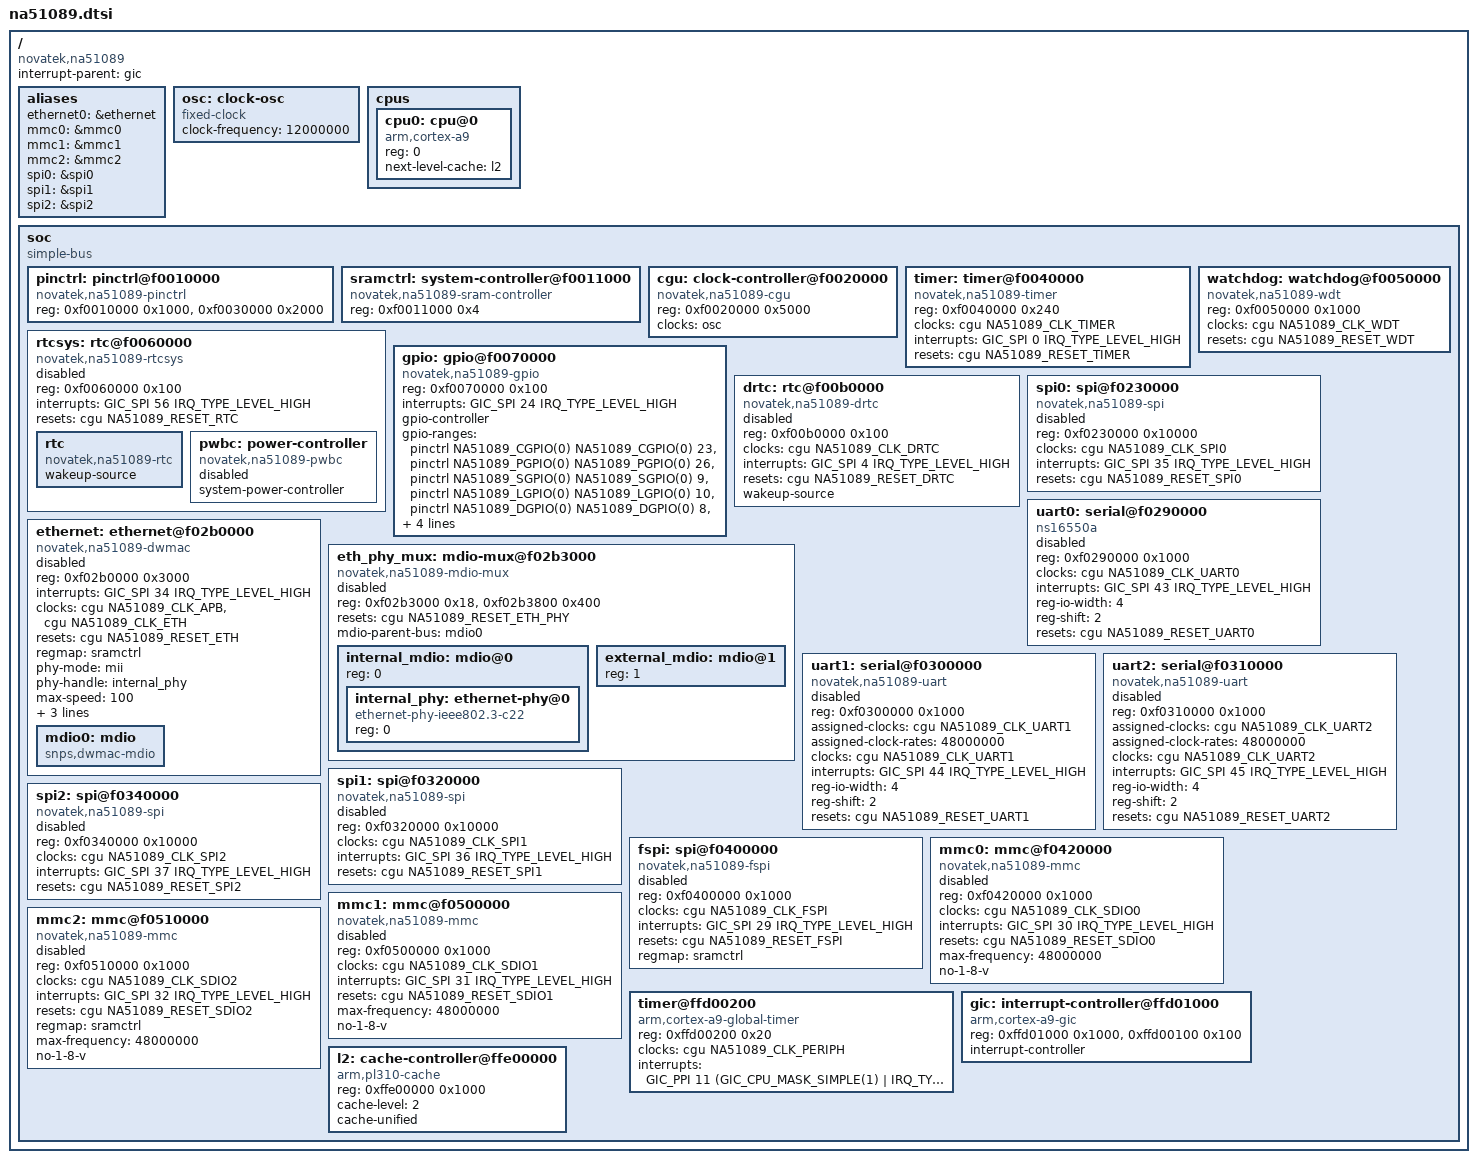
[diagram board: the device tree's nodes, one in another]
// SPDX-License-Identifier: (GPL-2.0-only OR BSD-2-Clause)

#include <dt-bindings/clock/novatek,na51089-clock.h>
#include <dt-bindings/gpio/novatek,na51089-gpio.h>
#include <dt-bindings/interrupt-controller/arm-gic.h>
#include <dt-bindings/interrupt-controller/irq.h>
#include <dt-bindings/reset/novatek,na51089-reset.h>

/ {
	compatible = "novatek,na51089";
	#address-cells = <1>;
	#size-cells = <1>;
	interrupt-parent = <&gic>;

	aliases {
		ethernet0 = &ethernet;
		mmc0 = &mmc0;
		mmc1 = &mmc1;
		mmc2 = &mmc2;
		spi0 = &spi0;
		spi1 = &spi1;
		spi2 = &spi2;
	};

	osc: clock-osc {
		compatible = "fixed-clock";
		#clock-cells = <0>;
		clock-frequency = <12000000>;
	};

	cpus {
		#address-cells = <1>;
		#size-cells = <0>;

		cpu0: cpu@0 {
			compatible = "arm,cortex-a9";
			reg = <0>;
			device_type = "cpu";
			next-level-cache = <&l2>;
		};
	};

	soc {
		compatible = "simple-bus";
		ranges;
		#address-cells = <1>;
		#size-cells = <1>;

		pinctrl: pinctrl@f0010000 {
			compatible = "novatek,na51089-pinctrl";
			reg = <0xf0010000 0x1000>,
			      <0xf0030000 0x2000>;
			reg-names = "top", "pad";
		};

		sramctrl: system-controller@f0011000 {
			compatible = "novatek,na51089-sram-controller", "syscon";
			reg = <0xf0011000 0x4>;
		};

		cgu: clock-controller@f0020000 {
			compatible = "novatek,na51089-cgu";
			reg = <0xf0020000 0x5000>;
			clocks = <&osc>;
			clock-names = "osc";
			#clock-cells = <1>;
			#reset-cells = <1>;
		};

		timer: timer@f0040000 {
			compatible = "novatek,na51089-timer";
			reg = <0xf0040000 0x240>;
			clocks = <&cgu NA51089_CLK_TIMER>;
			interrupts = <GIC_SPI 0 IRQ_TYPE_LEVEL_HIGH>;
			resets = <&cgu NA51089_RESET_TIMER>;
		};

		watchdog: watchdog@f0050000 {
			compatible = "novatek,na51089-wdt";
			reg = <0xf0050000 0x1000>;
			clocks = <&cgu NA51089_CLK_WDT>;
			resets = <&cgu NA51089_RESET_WDT>;
		};

		rtcsys: rtc@f0060000 {
			compatible = "novatek,na51089-rtcsys";
			reg = <0xf0060000 0x100>;
			interrupts = <GIC_SPI 56 IRQ_TYPE_LEVEL_HIGH>;
			resets = <&cgu NA51089_RESET_RTC>;
			status = "disabled";

			rtc: rtc {
				compatible = "novatek,na51089-rtc";
				wakeup-source;
			};

			pwbc: power-controller {
				compatible = "novatek,na51089-pwbc";
				system-power-controller;
				status = "disabled";
			};
		};

		gpio: gpio@f0070000 {
			compatible = "novatek,na51089-gpio";
			reg = <0xf0070000 0x100>;
			interrupts = <GIC_SPI 24 IRQ_TYPE_LEVEL_HIGH>;
			gpio-controller;
			#gpio-cells = <2>;
			gpio-ranges = <&pinctrl NA51089_CGPIO(0) NA51089_CGPIO(0) 23>,
				      <&pinctrl NA51089_PGPIO(0) NA51089_PGPIO(0) 26>,
				      <&pinctrl NA51089_SGPIO(0) NA51089_SGPIO(0) 9>,
				      <&pinctrl NA51089_LGPIO(0) NA51089_LGPIO(0) 10>,
				      <&pinctrl NA51089_DGPIO(0) NA51089_DGPIO(0) 8>,
				      <&pinctrl NA51089_HGPIO(0) NA51089_HGPIO(0) 12>,
				      <&pinctrl NA51089_AGPIO(0) NA51089_AGPIO(0) 3>,
				      <&pinctrl NA51089_DSIGPIO(0) NA51089_DSIGPIO(0) 11>;
			interrupt-controller;
			#address-cells = <0>;
			#interrupt-cells = <2>;
		};

		drtc: rtc@f00b0000 {
			compatible = "novatek,na51089-drtc";
			reg = <0xf00b0000 0x100>;
			clocks = <&cgu NA51089_CLK_DRTC>;
			interrupts = <GIC_SPI 4 IRQ_TYPE_LEVEL_HIGH>;
			resets = <&cgu NA51089_RESET_DRTC>;
			wakeup-source;
			status = "disabled";
		};

		spi0: spi@f0230000 {
			compatible = "novatek,na51089-spi";
			reg = <0xf0230000 0x10000>;
			clocks = <&cgu NA51089_CLK_SPI0>;
			interrupts = <GIC_SPI 35 IRQ_TYPE_LEVEL_HIGH>;
			resets = <&cgu NA51089_RESET_SPI0>;
			#address-cells = <1>;
			#size-cells = <0>;
			status = "disabled";
		};

		uart0: serial@f0290000 {
			compatible = "ns16550a";
			reg = <0xf0290000 0x1000>;
			clocks = <&cgu NA51089_CLK_UART0>;
			interrupts = <GIC_SPI 43 IRQ_TYPE_LEVEL_HIGH>;
			reg-io-width = <4>;
			reg-shift = <2>;
			resets = <&cgu NA51089_RESET_UART0>;
			status = "disabled";
		};

		ethernet: ethernet@f02b0000 {
			compatible = "novatek,na51089-dwmac";
			reg = <0xf02b0000 0x3000>;
			reg-names = "mac";
			interrupts = <GIC_SPI 34 IRQ_TYPE_LEVEL_HIGH>;
			interrupt-names = "macirq";
			clocks = <&cgu NA51089_CLK_APB>,
				 <&cgu NA51089_CLK_ETH>;
			clock-names = "stmmaceth", "ethref";
			resets = <&cgu NA51089_RESET_ETH>;
			reset-names = "stmmaceth";
			regmap = <&sramctrl>;
			phy-mode = "mii";
			phy-handle = <&internal_phy>;
			max-speed = <100>;
			snps,pbl = <16>;
			snps,no-pbl-x8;
			snps,force_sf_dma_mode;
			status = "disabled";

			mdio0: mdio {
				compatible = "snps,dwmac-mdio";
				#address-cells = <1>;
				#size-cells = <0>;
			};
		};

		eth_phy_mux: mdio-mux@f02b3000 {
			compatible = "novatek,na51089-mdio-mux";
			reg = <0xf02b3000 0x18>,
			      <0xf02b3800 0x400>;
			reg-names = "mux", "phy";
			resets = <&cgu NA51089_RESET_ETH_PHY>;
			reset-names = "phy";
			mdio-parent-bus = <&mdio0>;
			#address-cells = <1>;
			#size-cells = <0>;
			status = "disabled";

			internal_mdio: mdio@0 {
				reg = <0>;
				#address-cells = <1>;
				#size-cells = <0>;

				internal_phy: ethernet-phy@0 {
					compatible = "ethernet-phy-ieee802.3-c22";
					reg = <0>;
				};
			};

			external_mdio: mdio@1 {
				reg = <1>;
				#address-cells = <1>;
				#size-cells = <0>;
			};
		};

		uart1: serial@f0300000 {
			compatible = "novatek,na51089-uart";
			reg = <0xf0300000 0x1000>;
			assigned-clocks = <&cgu NA51089_CLK_UART1>;
			assigned-clock-rates = <48000000>;
			clocks = <&cgu NA51089_CLK_UART1>;
			interrupts = <GIC_SPI 44 IRQ_TYPE_LEVEL_HIGH>;
			reg-io-width = <4>;
			reg-shift = <2>;
			resets = <&cgu NA51089_RESET_UART1>;
			status = "disabled";
		};

		uart2: serial@f0310000 {
			compatible = "novatek,na51089-uart";
			reg = <0xf0310000 0x1000>;
			assigned-clocks = <&cgu NA51089_CLK_UART2>;
			assigned-clock-rates = <48000000>;
			clocks = <&cgu NA51089_CLK_UART2>;
			interrupts = <GIC_SPI 45 IRQ_TYPE_LEVEL_HIGH>;
			reg-io-width = <4>;
			reg-shift = <2>;
			resets = <&cgu NA51089_RESET_UART2>;
			status = "disabled";
		};

		spi1: spi@f0320000 {
			compatible = "novatek,na51089-spi";
			reg = <0xf0320000 0x10000>;
			clocks = <&cgu NA51089_CLK_SPI1>;
			interrupts = <GIC_SPI 36 IRQ_TYPE_LEVEL_HIGH>;
			resets = <&cgu NA51089_RESET_SPI1>;
			#address-cells = <1>;
			#size-cells = <0>;
			status = "disabled";
		};

		spi2: spi@f0340000 {
			compatible = "novatek,na51089-spi";
			reg = <0xf0340000 0x10000>;
			clocks = <&cgu NA51089_CLK_SPI2>;
			interrupts = <GIC_SPI 37 IRQ_TYPE_LEVEL_HIGH>;
			resets = <&cgu NA51089_RESET_SPI2>;
			#address-cells = <1>;
			#size-cells = <0>;
			status = "disabled";
		};

		fspi: spi@f0400000 {
			compatible = "novatek,na51089-fspi";
			reg = <0xf0400000 0x1000>;
			clocks = <&cgu NA51089_CLK_FSPI>;
			interrupts = <GIC_SPI 29 IRQ_TYPE_LEVEL_HIGH>;
			resets = <&cgu NA51089_RESET_FSPI>;
			regmap = <&sramctrl>;
			#address-cells = <1>;
			#size-cells = <0>;
			status = "disabled";
		};

		mmc0: mmc@f0420000 {
			compatible = "novatek,na51089-mmc";
			reg = <0xf0420000 0x1000>;
			clocks = <&cgu NA51089_CLK_SDIO0>;
			interrupts = <GIC_SPI 30 IRQ_TYPE_LEVEL_HIGH>;
			resets = <&cgu NA51089_RESET_SDIO0>;
			max-frequency = <48000000>;
			no-1-8-v;
			#address-cells = <1>;
			#size-cells = <0>;
			status = "disabled";
		};

		mmc1: mmc@f0500000 {
			compatible = "novatek,na51089-mmc";
			reg = <0xf0500000 0x1000>;
			clocks = <&cgu NA51089_CLK_SDIO1>;
			interrupts = <GIC_SPI 31 IRQ_TYPE_LEVEL_HIGH>;
			resets = <&cgu NA51089_RESET_SDIO1>;
			max-frequency = <48000000>;
			no-1-8-v;
			#address-cells = <1>;
			#size-cells = <0>;
			status = "disabled";
		};

		mmc2: mmc@f0510000 {
			compatible = "novatek,na51089-mmc";
			reg = <0xf0510000 0x1000>;
			clocks = <&cgu NA51089_CLK_SDIO2>;
			interrupts = <GIC_SPI 32 IRQ_TYPE_LEVEL_HIGH>;
			resets = <&cgu NA51089_RESET_SDIO2>;
			regmap = <&sramctrl>;
			max-frequency = <48000000>;
			no-1-8-v;
			#address-cells = <1>;
			#size-cells = <0>;
			status = "disabled";
		};

		timer@ffd00200 {
			compatible = "arm,cortex-a9-global-timer";
			reg = <0xffd00200 0x20>;
			clocks = <&cgu NA51089_CLK_PERIPH>;
			interrupts = <GIC_PPI 11
				      (GIC_CPU_MASK_SIMPLE(1) | IRQ_TYPE_EDGE_RISING)>;
		};

		gic: interrupt-controller@ffd01000 {
			compatible = "arm,cortex-a9-gic";
			reg = <0xffd01000 0x1000>,
			      <0xffd00100 0x100>;
			#address-cells = <0>;
			#interrupt-cells = <3>;
			interrupt-controller;
		};

		l2: cache-controller@ffe00000 {
			compatible = "arm,pl310-cache";
			reg = <0xffe00000 0x1000>;
			cache-level = <2>;
			cache-unified;
		};
	};
};

#include "na51089-pinctrl.dtsi"
